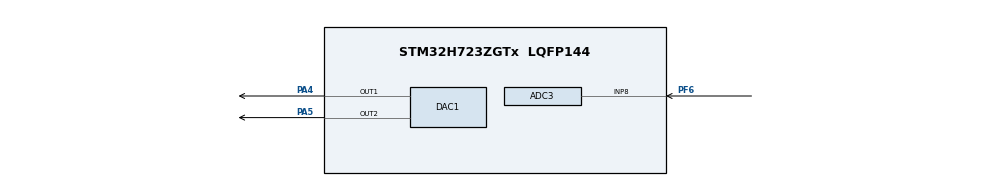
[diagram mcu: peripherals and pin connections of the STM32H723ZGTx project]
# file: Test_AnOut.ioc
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ADC3.Channel-0\#ChannelRegularConversion=ADC_CHANNEL_8
ADC3.ContinuousConvMode=ENABLE
ADC3.NbrOfConversionFlag=1
ADC3.OffsetNumber-0\#ChannelRegularConversion=ADC_OFFSET_NONE
ADC3.OffsetSign-0\#ChannelRegularConversion=ADC3_OFFSET_SIGN_NEGATIVE
ADC3.Overrun=ADC_OVR_DATA_OVERWRITTEN
ADC3.Rank-0\#ChannelRegularConversion=1
ADC3.SamplingTime-0\#ChannelRegularConversion=ADC3_SAMPLETIME_2CYCLES_5
CORTEX_M7.default_mode_Activation=1
DAC1.DAC_Channel-DAC_OUT1=DAC_CHANNEL_1
DAC1.DAC_Channel-DAC_OUT2=DAC_CHANNEL_2
DAC1.DAC_Trigger-DAC_OUT1=DAC_TRIGGER_T6_TRGO
DAC1.DAC_Trigger-DAC_OUT2=DAC_TRIGGER_T6_TRGO
Dma.DAC1_CH1.0.Direction=DMA_MEMORY_TO_PERIPH
Dma.DAC1_CH1.0.EventEnable=DISABLE
Dma.DAC1_CH1.0.FIFOMode=DMA_FIFOMODE_DISABLE
Dma.DAC1_CH1.0.Instance=DMA1_Stream0
Dma.DAC1_CH1.0.MemDataAlignment=DMA_MDATAALIGN_WORD
Dma.DAC1_CH1.0.MemInc=DMA_MINC_ENABLE
Dma.DAC1_CH1.0.Mode=DMA_CIRCULAR
Dma.DAC1_CH1.0.PeriphDataAlignment=DMA_PDATAALIGN_WORD
Dma.DAC1_CH1.0.PeriphInc=DMA_PINC_DISABLE
Dma.DAC1_CH1.0.Polarity=HAL_DMAMUX_REQ_GEN_RISING
Dma.DAC1_CH1.0.Priority=DMA_PRIORITY_LOW
Dma.DAC1_CH1.0.RequestNumber=1
Dma.DAC1_CH1.0.SignalID=NONE
Dma.DAC1_CH1.0.SyncEnable=DISABLE
Dma.DAC1_CH1.0.SyncPolarity=HAL_DMAMUX_SYNC_NO_EVENT
Dma.DAC1_CH1.0.SyncRequestNumber=1
Dma.DAC1_CH1.0.SyncSignalID=NONE
Dma.DAC1_CH2.1.Direction=DMA_MEMORY_TO_PERIPH
Dma.DAC1_CH2.1.EventEnable=DISABLE
Dma.DAC1_CH2.1.FIFOMode=DMA_FIFOMODE_DISABLE
Dma.DAC1_CH2.1.Instance=DMA1_Stream1
Dma.DAC1_CH2.1.MemDataAlignment=DMA_MDATAALIGN_WORD
Dma.DAC1_CH2.1.MemInc=DMA_MINC_ENABLE
Dma.DAC1_CH2.1.Mode=DMA_CIRCULAR
Dma.DAC1_CH2.1.PeriphDataAlignment=DMA_PDATAALIGN_WORD
Dma.DAC1_CH2.1.PeriphInc=DMA_PINC_DISABLE
Dma.DAC1_CH2.1.Polarity=HAL_DMAMUX_REQ_GEN_RISING
Dma.DAC1_CH2.1.Priority=DMA_PRIORITY_LOW
Dma.DAC1_CH2.1.RequestNumber=1
Dma.DAC1_CH2.1.SignalID=NONE
Dma.DAC1_CH2.1.SyncEnable=DISABLE
Dma.DAC1_CH2.1.SyncPolarity=HAL_DMAMUX_SYNC_NO_EVENT
Dma.DAC1_CH2.1.SyncRequestNumber=1
Dma.DAC1_CH2.1.SyncSignalID=NONE
Dma.Request0=DAC1_CH1
Dma.Request1=DAC1_CH2
Mcu.Family=STM32H7
Mcu.Name=STM32H723ZGTx
Mcu.Package=LQFP144
NVIC.PriorityGroup=NVIC_PRIORITYGROUP_4
NVIC.TIM6_DAC_IRQn=true\:0\:0\:false\:false\:true\:true\:true\:true
PA4.Signal=COMP_DAC11_group
PA5.Signal=COMP_DAC12_group
PF6.Mode=IN8-Single-Ended
PF6.Signal=ADC3_INP8
ProjectManager.HeapSize=0x200
ProjectManager.StackSize=0x400
ProjectManager.TargetToolchain=STM32CubeIDE
RCC.ADCFreq_Value=129000000
RCC.APB1Freq_Value=125000000
RCC.APB2Freq_Value=125000000
RCC.APB3Freq_Value=125000000
RCC.APB4Freq_Value=125000000
RCC.CortexFreq_Value=500000000
RCC.D1PPRE=RCC_APB3_DIV2
RCC.D2PPRE1=RCC_APB1_DIV2
RCC.D2PPRE2=RCC_APB2_DIV2
RCC.D3PPRE=RCC_APB4_DIV2
RCC.DIVM1=4
RCC.DIVN1=31
RCC.DIVP1=1
RCC.HCLKFreq_Value=250000000
RCC.HPRE=RCC_HCLK_DIV2
RCC.PLLFRACN=2048
RCC.SYSCLKFreq_VALUE=500000000
RCC.SYSCLKSource=RCC_SYSCLKSOURCE_PLLCLK
RCC.USBFreq_Value=250000000
SH.COMP_DAC11_group.0=DAC1_OUT1,DAC_OUT1
SH.COMP_DAC12_group.0=DAC1_OUT2,DAC_OUT2
TIM6.Period=999
TIM6.Prescaler=274
TIM6.TIM_MasterOutputTrigger=TIM_TRGO_UPDATE
VP_MEMORYMAP_VS_MEMORYMAP.Mode=CurAppReg
VP_TIM6_VS_ClockSourceINT.Mode=Enable_Timer
board=custom

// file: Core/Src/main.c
/* USER CODE BEGIN Header */
/**
  ******************************************************************************
  * @file           : main.c
  * @brief          : Main program body
  ******************************************************************************
  * @attention
  *
  * Copyright (c) 2025 STMicroelectronics.
  * All rights reserved.
  *
  * This software is licensed under terms that can be found in the LICENSE file
  * in the root directory of this software component.
  * If no LICENSE file comes with this software, it is provided AS-IS.
  *
  ******************************************************************************
  */
/* USER CODE END Header */
#include "main.h"

/* USER CODE BEGIN Includes */
#include "math.h"
#include "stdlib.h"
/* USER CODE END Includes */

/* USER CODE BEGIN PTD */
#define SAMPLES 1000
/* USER CODE END PTD */

/* USER CODE BEGIN PD */
uint32_t signal1_values[SAMPLES];
uint32_t signal2_values[SAMPLES];
volatile float Raw_Sine_Wave ;
volatile float RC_Filter_Output ;
volatile float Raw_Sine_Wave_old ;
volatile float RC_Filter_Output_old ;
volatile float noise;
/* USER CODE END PD */

ADC_HandleTypeDef hadc3;

DAC_HandleTypeDef hdac1;
DMA_HandleTypeDef hdma_dac1_ch1;
DMA_HandleTypeDef hdma_dac1_ch2;

TIM_HandleTypeDef htim6;

void SystemClock_Config(void);
static void MPU_Config(void);
static void MX_GPIO_Init(void);
static void MX_DMA_Init(void);
static void MX_DAC1_Init(void);
static void MX_TIM6_Init(void);
static void MX_ADC3_Init(void);

int main(void)
{

  /* MPU Configuration--------------------------------------------------------*/
  MPU_Config();

  /* MCU Configuration--------------------------------------------------------*/

  /* Reset of all peripherals, Initializes the Flash interface and the Systick. */
  HAL_Init();

  /* Configure the system clock */
  SystemClock_Config();

  /* Initialize all configured peripherals */
  MX_GPIO_Init();
  MX_DMA_Init();
  MX_DAC1_Init();
  MX_TIM6_Init();
  MX_ADC3_Init();
  /* USER CODE BEGIN 2 */
  for ( int i = 0; i < SAMPLES; i++ )
  {
	  signal1_values[i] = ( uint32_t )( ( 0.5 + 0.5 * sin ( 2*3.14159*i/SAMPLES + noise ) ) * 4095 );
	  noise = ((float)rand() / RAND_MAX - 0.5f) * 0.25f;
  }

  HAL_DAC_Start_DMA ( &hdac1, DAC_CHANNEL_1, ( const uint32_t* )&signal1_values[0], SAMPLES, DAC_ALIGN_12B_R );
  HAL_TIM_Base_Start_IT ( &htim6 );
  HAL_ADC_Start(&hadc3);
  /* USER CODE END 2 */

  /* Infinite loop */
  while (1)
  {

  }
}

void SystemClock_Config(void)
{
  RCC_OscInitTypeDef RCC_OscInitStruct = {0};
  RCC_ClkInitTypeDef RCC_ClkInitStruct = {0};

  /** Supply configuration update enable
  */
  HAL_PWREx_ConfigSupply(PWR_LDO_SUPPLY);

  /** Configure the main internal regulator output voltage
  */
  __HAL_PWR_VOLTAGESCALING_CONFIG(PWR_REGULATOR_VOLTAGE_SCALE0);

  while(!__HAL_PWR_GET_FLAG(PWR_FLAG_VOSRDY)) {}

  /** Initializes the RCC Oscillators according to the specified parameters
  * in the RCC_OscInitTypeDef structure.
  */
  RCC_OscInitStruct.OscillatorType = RCC_OSCILLATORTYPE_HSI;
  RCC_OscInitStruct.HSIState = RCC_HSI_DIV1;
  RCC_OscInitStruct.HSICalibrationValue = 64;
  RCC_OscInitStruct.PLL.PLLState = RCC_PLL_ON;
  RCC_OscInitStruct.PLL.PLLSource = RCC_PLLSOURCE_HSI;
  RCC_OscInitStruct.PLL.PLLM = 4;
  RCC_OscInitStruct.PLL.PLLN = 31;
  RCC_OscInitStruct.PLL.PLLP = 1;
  RCC_OscInitStruct.PLL.PLLQ = 2;
  RCC_OscInitStruct.PLL.PLLR = 2;
  RCC_OscInitStruct.PLL.PLLRGE = RCC_PLL1VCIRANGE_3;
  RCC_OscInitStruct.PLL.PLLVCOSEL = RCC_PLL1VCOWIDE;
  RCC_OscInitStruct.PLL.PLLFRACN = 2048;
  if (HAL_RCC_OscConfig(&RCC_OscInitStruct) != HAL_OK)
  {
    Error_Handler();
  }

  /** Initializes the CPU, AHB and APB buses clocks
  */
  RCC_ClkInitStruct.ClockType = RCC_CLOCKTYPE_HCLK|RCC_CLOCKTYPE_SYSCLK
                              |RCC_CLOCKTYPE_PCLK1|RCC_CLOCKTYPE_PCLK2
                              |RCC_CLOCKTYPE_D3PCLK1|RCC_CLOCKTYPE_D1PCLK1;
  RCC_ClkInitStruct.SYSCLKSource = RCC_SYSCLKSOURCE_PLLCLK;
  RCC_ClkInitStruct.SYSCLKDivider = RCC_SYSCLK_DIV1;
  RCC_ClkInitStruct.AHBCLKDivider = RCC_HCLK_DIV2;
  RCC_ClkInitStruct.APB3CLKDivider = RCC_APB3_DIV2;
  RCC_ClkInitStruct.APB1CLKDivider = RCC_APB1_DIV2;
  RCC_ClkInitStruct.APB2CLKDivider = RCC_APB2_DIV2;
  RCC_ClkInitStruct.APB4CLKDivider = RCC_APB4_DIV2;

  if (HAL_RCC_ClockConfig(&RCC_ClkInitStruct, FLASH_LATENCY_3) != HAL_OK)
  {
    Error_Handler();
  }
}

static void MX_ADC3_Init(void)
{

  ADC_ChannelConfTypeDef sConfig = {0};

  /** Common config
  */
  hadc3.Instance = ADC3;
  hadc3.Init.ClockPrescaler = ADC_CLOCK_ASYNC_DIV1;
  hadc3.Init.Resolution = ADC_RESOLUTION_12B;
  hadc3.Init.DataAlign = ADC3_DATAALIGN_RIGHT;
  hadc3.Init.ScanConvMode = ADC_SCAN_DISABLE;
  hadc3.Init.EOCSelection = ADC_EOC_SINGLE_CONV;
  hadc3.Init.LowPowerAutoWait = DISABLE;
  hadc3.Init.ContinuousConvMode = ENABLE;
  hadc3.Init.NbrOfConversion = 1;
  hadc3.Init.DiscontinuousConvMode = DISABLE;
  hadc3.Init.ExternalTrigConv = ADC_SOFTWARE_START;
  hadc3.Init.ExternalTrigConvEdge = ADC_EXTERNALTRIGCONVEDGE_NONE;
  hadc3.Init.DMAContinuousRequests = DISABLE;
  hadc3.Init.SamplingMode = ADC_SAMPLING_MODE_NORMAL;
  hadc3.Init.ConversionDataManagement = ADC_CONVERSIONDATA_DR;
  hadc3.Init.Overrun = ADC_OVR_DATA_OVERWRITTEN;
  hadc3.Init.LeftBitShift = ADC_LEFTBITSHIFT_NONE;
  hadc3.Init.OversamplingMode = DISABLE;
  hadc3.Init.Oversampling.Ratio = ADC3_OVERSAMPLING_RATIO_2;
  if (HAL_ADC_Init(&hadc3) != HAL_OK)
  {
    Error_Handler();
  }

  /** Configure Regular Channel
  */
  sConfig.Channel = ADC_CHANNEL_8;
  sConfig.Rank = ADC_REGULAR_RANK_1;
  sConfig.SamplingTime = ADC3_SAMPLETIME_2CYCLES_5;
  sConfig.SingleDiff = ADC_SINGLE_ENDED;
  sConfig.OffsetNumber = ADC_OFFSET_NONE;
  sConfig.Offset = 0;
  sConfig.OffsetSign = ADC3_OFFSET_SIGN_NEGATIVE;
  if (HAL_ADC_ConfigChannel(&hadc3, &sConfig) != HAL_OK)
  {
    Error_Handler();
  }

}

static void MX_DAC1_Init(void)
{

  DAC_ChannelConfTypeDef sConfig = {0};

  /** DAC Initialization
  */
  hdac1.Instance = DAC1;
  if (HAL_DAC_Init(&hdac1) != HAL_OK)
  {
    Error_Handler();
  }

  /** DAC channel OUT1 config
  */
  sConfig.DAC_SampleAndHold = DAC_SAMPLEANDHOLD_DISABLE;
  sConfig.DAC_Trigger = DAC_TRIGGER_T6_TRGO;
  sConfig.DAC_OutputBuffer = DAC_OUTPUTBUFFER_ENABLE;
  sConfig.DAC_ConnectOnChipPeripheral = DAC_CHIPCONNECT_DISABLE;
  sConfig.DAC_UserTrimming = DAC_TRIMMING_FACTORY;
  if (HAL_DAC_ConfigChannel(&hdac1, &sConfig, DAC_CHANNEL_1) != HAL_OK)
  {
    Error_Handler();
  }

  /** DAC channel OUT2 config
  */
  if (HAL_DAC_ConfigChannel(&hdac1, &sConfig, DAC_CHANNEL_2) != HAL_OK)
  {
    Error_Handler();
  }

}

static void MX_TIM6_Init(void)
{

  TIM_MasterConfigTypeDef sMasterConfig = {0};

  htim6.Instance = TIM6;
  htim6.Init.Prescaler = 274;
  htim6.Init.CounterMode = TIM_COUNTERMODE_UP;
  htim6.Init.Period = 999;
  htim6.Init.AutoReloadPreload = TIM_AUTORELOAD_PRELOAD_DISABLE;
  if (HAL_TIM_Base_Init(&htim6) != HAL_OK)
  {
    Error_Handler();
  }
  sMasterConfig.MasterOutputTrigger = TIM_TRGO_UPDATE;
  sMasterConfig.MasterSlaveMode = TIM_MASTERSLAVEMODE_DISABLE;
  if (HAL_TIMEx_MasterConfigSynchronization(&htim6, &sMasterConfig) != HAL_OK)
  {
    Error_Handler();
  }

}

static void MX_DMA_Init(void)
{

  /* DMA controller clock enable */
  __HAL_RCC_DMA1_CLK_ENABLE();

}

static void MX_GPIO_Init(void)
{

  /* GPIO Ports Clock Enable */
  __HAL_RCC_GPIOF_CLK_ENABLE();
  __HAL_RCC_GPIOA_CLK_ENABLE();

}

/* USER CODE BEGIN 4 */
void HAL_TIM_PeriodElapsedCallback( TIM_HandleTypeDef *htim ) //Fs = 2500 Hz
{
	Raw_Sine_Wave = (3.3 / 4095 ) * HAL_ADC_GetValue(&hadc3) ;
	RC_Filter_Output = 0.006211 * Raw_Sine_Wave + 0.006211 * Raw_Sine_Wave_old + 0.9876 * RC_Filter_Output_old;
	Raw_Sine_Wave_old = Raw_Sine_Wave;
	RC_Filter_Output_old = RC_Filter_Output;
}
/* USER CODE END 4 */

 /* MPU Configuration */

void MPU_Config(void)
{
  MPU_Region_InitTypeDef MPU_InitStruct = {0};

  /* Disables the MPU */
  HAL_MPU_Disable();

  /** Initializes and configures the Region and the memory to be protected
  */
  MPU_InitStruct.Enable = MPU_REGION_ENABLE;
  MPU_InitStruct.Number = MPU_REGION_NUMBER0;
  MPU_InitStruct.BaseAddress = 0x0;
  MPU_InitStruct.Size = MPU_REGION_SIZE_4GB;
  MPU_InitStruct.SubRegionDisable = 0x87;
  MPU_InitStruct.TypeExtField = MPU_TEX_LEVEL0;
  MPU_InitStruct.AccessPermission = MPU_REGION_NO_ACCESS;
  MPU_InitStruct.DisableExec = MPU_INSTRUCTION_ACCESS_DISABLE;
  MPU_InitStruct.IsShareable = MPU_ACCESS_SHAREABLE;
  MPU_InitStruct.IsCacheable = MPU_ACCESS_NOT_CACHEABLE;
  MPU_InitStruct.IsBufferable = MPU_ACCESS_NOT_BUFFERABLE;

  HAL_MPU_ConfigRegion(&MPU_InitStruct);
  /* Enables the MPU */
  HAL_MPU_Enable(MPU_PRIVILEGED_DEFAULT);

}

void Error_Handler(void)
{
  __disable_irq();
  while (1)
  {
  }
}
